VERSION ""

NS_ :

BS_:

BU_: ACU Charger Charging_SDC DGPS DTI_Inverter Dash_Panel Debugger ECU Energy_Meter Fan_Controller_1 Fan_Controller_2 Fan_Controller_3 Fan_Controller_4 Fan_Controller_5 Fan_Controller_6 Fan_Controller_7 Fan_Controller_8 GR_Inverter_1 GR_Inverter_2 GR_Inverter_3 GR_Inverter_4 IMD LV_DC_DC SAM1 SAM10 SAM11 SAM12 SAM13 SAM14 SAM15 SAM16 SAM17 SAM18 SAM19 SAM2 SAM20 SAM3 SAM4 SAM5 SAM6 SAM7 SAM8 SAM9 Steering_Wheel TCM ALL

BO_ 2147680257 ACU_Debug_2_0_to_Debugger: 8 ACU
 SG_ Debug : 0|64@1- (1,0) [0|0] "" Debugger

BO_ 2147680769 ACU_Ping_to_Debugger: 4 ACU
 SG_ Timestamp : 0|32@1+ (1,0) [0|4,294,967,296] "ms" Debugger

BO_ 2147680770 ACU_Ping_to_ECU: 4 ACU
 SG_ Timestamp : 0|32@1+ (1,0) [0|4,294,967,296] "ms" ECU

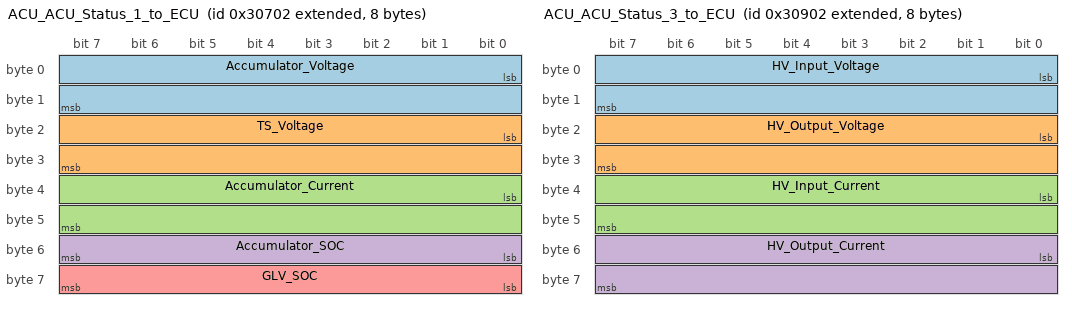
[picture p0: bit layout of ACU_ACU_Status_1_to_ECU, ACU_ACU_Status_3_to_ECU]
BO_ 2147682050 ACU_ACU_Status_1_to_ECU: 8 ACU
 SG_ Accumulator_Voltage : 0|16@1+ (0.01,0) [0|655.35] "Volts" ECU
 SG_ TS_Voltage : 16|16@1+ (0.01,0) [0|655.35] "Volts" ECU
 SG_ Accumulator_Current : 32|16@1- (0.01,0) [-327.68|327.67] "Amps" ECU
 SG_ Accumulator_SOC : 48|8@1+ (0.392157,0) [0|100] "%" ECU
 SG_ GLV_SOC : 56|8@1+ (0.392157,0) [0|100] "%" ECU

BO_ 2147682306 ACU_ACU_Status_2_to_ECU: 7 ACU
 SG_ 20v_Voltage : 0|8@1+ (0.1,0) [0|25.5] "Volts" ECU
 SG_ 12v_Voltage : 8|8@1+ (0.1,0) [0|25.5] "Volts" ECU
 SG_ SDC_Voltage : 16|8@1+ (0.1,0) [0|25.5] "Volts" ECU
 SG_ Min_Cell_Voltage : 24|8@1+ (0.01,2) [2|4.55] "Volts" ECU
 SG_ Max_Cell_Temp : 32|8@1+ (0.25,0) [0|63.75] "Celsius" ECU
 SG_ Over_Temp_Error : 40|1@1+ (1,0) [0|0] "Bool" ECU
 SG_ Over_Voltage_Error : 41|1@1+ (1,0) [0|0] "Bool" ECU
 SG_ Under_Voltage_Error : 42|1@1+ (1,0) [0|0] "Bool" ECU
 SG_ Over_Current_Error : 43|1@1+ (1,0) [0|0] "Bool" ECU
 SG_ Under_Current_Error : 44|1@1+ (1,0) [0|0] "Bool" ECU
 SG_ Under_Voltage_20v_Warning : 45|1@1+ (1,0) [0|0] "Bool" ECU
 SG_ Under_Voltage_12v_Warning : 46|1@1+ (1,0) [0|0] "Bool" ECU
 SG_ Under_Voltage_SDC_Warning : 47|1@1+ (1,0) [0|0] "Bool" ECU
 SG_ Precharge_Error : 48|1@1+ (1,0) [0|0] "Bool" ECU
 SG_ IR__Precharge_State : 49|1@1+ (1,0) [0|0] "Bool" ECU
 SG_ IR_State : 50|1@1+ (1,0) [0|0] "Bool" ECU
 SG_ Software_Latch : 51|1@1+ (1,0) [0|0] "Bool" ECU

BO_ 2147682562 ACU_ACU_Status_3_to_ECU: 8 ACU
 SG_ HV_Input_Voltage : 0|16@1+ (0.01,0) [0|655.35] "Volts" ECU
 SG_ HV_Output_Voltage : 16|16@1+ (0.01,0) [0|655.35] "Volts" ECU
 SG_ HV_Input_Current : 32|16@1+ (0.001,0) [0|65.535] "Amps" ECU
 SG_ HV_Output_Current : 48|16@1+ (0.001,0) [0|65.535] "Amps" ECU

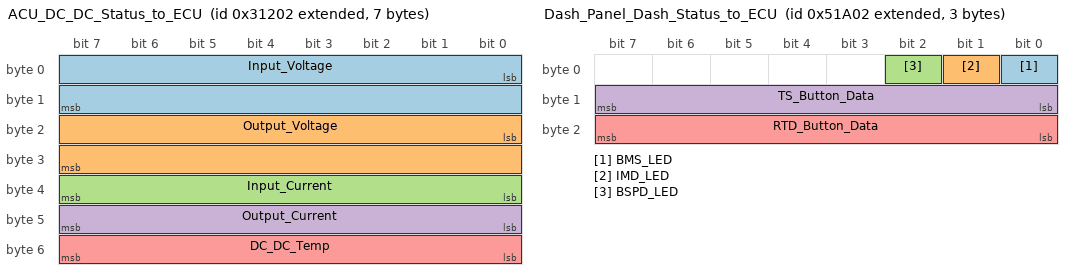
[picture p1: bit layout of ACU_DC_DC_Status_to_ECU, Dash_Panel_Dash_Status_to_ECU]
BO_ 2147684866 ACU_DC_DC_Status_to_ECU: 7 ACU
 SG_ Input_Voltage : 0|16@1+ (0.001,0) [0|65.535] "Volts" ECU
 SG_ Output_Voltage : 16|16@1+ (0.001,0) [0|65.535] "Volts" ECU
 SG_ Input_Current : 32|8@1+ (0.1,0) [0|25.5] "Amps" ECU
 SG_ Output_Current : 40|8@1+ (0.1,0) [0|25.5] "Amps" ECU
 SG_ DC_DC_Temp : 48|8@1+ (1,0) [0|255] "Celsius" ECU

BO_ 2147680513 ACU_Debug_FD_to_Debugger: 64 ACU
 SG_ Debug : 0|64@1- (1,0) [0|0] "" Debugger

BO_ 2147680769 ACU_Ping_to_Debugger: 4 ACU
 SG_ Timestamp : 0|32@1+ (1,0) [0|4,294,967,296] "ms" Debugger

BO_ 2147680770 ACU_Ping_to_ECU: 4 ACU
 SG_ Timestamp : 0|32@1+ (1,0) [0|4,294,967,296] "ms" ECU

BO_ 2147683839 ACU_ACU_Cell_Data_1_to_ALL: 64 ACU
 SG_ Cell_0_Voltage : 0|8@1+ (0.01,2) [2|4.55] "Volts" ALL
 SG_ Cell_0_Temp : 8|8@1+ (0.25,0) [0|63.75] "Celsius" ALL
 SG_ Cell_1_Voltage : 16|8@1+ (0.01,2) [2|4.55] "Volts" ALL
 SG_ Cell_1_Temp : 24|8@1+ (0.25,0) [0|63.75] "Celsius" ALL
 SG_ Cell_2_Voltage : 32|8@1+ (0.01,2) [2|4.55] "Volts" ALL
 SG_ Cell_2_Temp : 40|8@1+ (0.25,0) [0|63.75] "Celsius" ALL
 SG_ Cell_3_Voltage : 48|8@1+ (0.01,2) [2|4.55] "Volts" ALL
 SG_ Cell_3_Temp : 56|8@1+ (0.25,0) [0|63.75] "Celsius" ALL
 SG_ Cell_4_Voltage : 64|8@1+ (0.01,2) [2|4.55] "Volts" ALL
 SG_ Cell_4_Temp : 72|8@1+ (0.25,0) [0|63.75] "Celsius" ALL
 SG_ Cell_5_Voltage : 80|8@1+ (0.01,2) [2|4.55] "Volts" ALL
 SG_ Cell_5_Temp : 88|8@1+ (0.25,0) [0|63.75] "Celsius" ALL
 SG_ Cell_6_Voltage : 96|8@1+ (0.01,2) [2|4.55] "Volts" ALL
 SG_ Cell_6_Temp : 104|8@1+ (0.25,0) [0|63.75] "Celsius" ALL
 SG_ Cell_7_Voltage : 112|8@1+ (0.01,2) [2|4.55] "Volts" ALL
 SG_ Cell_7_Temp : 120|8@1+ (0.25,0) [0|63.75] "Celsius" ALL
 SG_ Cell_8_Voltage : 128|8@1+ (0.01,2) [2|4.55] "Volts" ALL
 SG_ Cell_8_Temp : 136|8@1+ (0.25,0) [0|63.75] "Celsius" ALL
 SG_ Cell_9_Voltage : 144|8@1+ (0.01,2) [2|4.55] "Volts" ALL
 SG_ Cell_9_Temp : 152|8@1+ (0.25,0) [0|63.75] "Celsius" ALL
 SG_ Cell_10_Voltage : 160|8@1+ (0.01,2) [2|4.55] "Volts" ALL
 SG_ Cell_10_Temp : 168|8@1+ (0.25,0) [0|63.75] "Celsius" ALL
 SG_ Cell_11_Voltage : 176|8@1+ (0.01,2) [2|4.55] "Volts" ALL
 SG_ Cell_11_Temp : 184|8@1+ (0.25,0) [0|63.75] "Celsius" ALL
 SG_ Cell_12_Voltage : 192|8@1+ (0.01,2) [2|4.55] "Volts" ALL
 SG_ Cell_12_Temp : 200|8@1+ (0.25,0) [0|63.75] "Celsius" ALL
 SG_ Cell_13_Voltage : 208|8@1+ (0.01,2) [2|4.55] "Volts" ALL
 SG_ Cell_13_Temp : 216|8@1+ (0.25,0) [0|63.75] "Celsius" ALL
 SG_ Cell_14_Voltage : 224|8@1+ (0.01,2) [2|4.55] "Volts" ALL
 SG_ Cell_14_Temp : 232|8@1+ (0.25,0) [0|63.75] "Celsius" ALL
 SG_ Cell_15_Voltage : 240|8@1+ (0.01,2) [2|4.55] "Volts" ALL
 SG_ Cell_15_Temp : 248|8@1+ (0.25,0) [0|63.75] "Celsius" ALL
 SG_ Cell_16_Voltage : 256|8@1+ (0.01,2) [2|4.55] "Volts" ALL
 SG_ Cell_16_Temp : 264|8@1+ (0.25,0) [0|63.75] "Celsius" ALL
 SG_ Cell_17_Voltage : 272|8@1+ (0.01,2) [2|4.55] "Volts" ALL
 SG_ Cell_17_Temp : 280|8@1+ (0.25,0) [0|63.75] "Celsius" ALL
 SG_ Cell_18_Voltage : 288|8@1+ (0.01,2) [2|4.55] "Volts" ALL
 SG_ Cell_18_Temp : 296|8@1+ (0.25,0) [0|63.75] "Celsius" ALL
 SG_ Cell_19_Voltage : 304|8@1+ (0.01,2) [2|4.55] "Volts" ALL
 SG_ Cell_19_Temp : 312|8@1+ (0.25,0) [0|63.75] "Celsius" ALL
 SG_ Cell_20_Voltage : 320|8@1+ (0.01,2) [2|4.55] "Volts" ALL
 SG_ Cell_20_Temp : 328|8@1+ (0.25,0) [0|63.75] "Celsius" ALL
 SG_ Cell_21_Voltage : 336|8@1+ (0.01,2) [2|4.55] "Volts" ALL
 SG_ Cell_21_Temp : 344|8@1+ (0.25,0) [0|63.75] "Celsius" ALL
 SG_ Cell_22_Voltage : 352|8@1+ (0.01,2) [2|4.55] "Volts" ALL
 SG_ Cell_22_Temp : 360|8@1+ (0.25,0) [0|63.75] "Celsius" ALL
 SG_ Cell_23_Voltage : 368|8@1+ (0.01,2) [2|4.55] "Volts" ALL
 SG_ Cell_23_Temp : 376|8@1+ (0.25,0) [0|63.75] "Celsius" ALL
 SG_ Cell_24_Voltage : 384|8@1+ (0.01,2) [2|4.55] "Volts" ALL
 SG_ Cell_24_Temp : 392|8@1+ (0.25,0) [0|63.75] "Celsius" ALL
 SG_ Cell_25_Voltage : 400|8@1+ (0.01,2) [2|4.55] "Volts" ALL
 SG_ Cell_25_Temp : 408|8@1+ (0.25,0) [0|63.75] "Celsius" ALL
 SG_ Cell_26_Voltage : 416|8@1+ (0.01,2) [2|4.55] "Volts" ALL
 SG_ Cell_26_Temp : 424|8@1+ (0.25,0) [0|63.75] "Celsius" ALL
 SG_ Cell_27_Voltage : 432|8@1+ (0.01,2) [2|4.55] "Volts" ALL
 SG_ Cell_27_Temp : 440|8@1+ (0.25,0) [0|63.75] "Celsius" ALL
 SG_ Cell_28_Voltage : 448|8@1+ (0.01,2) [2|4.55] "Volts" ALL
 SG_ Cell_28_Temp : 456|8@1+ (0.25,0) [0|63.75] "Celsius" ALL
 SG_ Cell_29_Voltage : 464|8@1+ (0.01,2) [2|4.55] "Volts" ALL
 SG_ Cell_29_Temp : 472|8@1+ (0.25,0) [0|63.75] "Celsius" ALL
 SG_ Cell_30_Voltage : 480|8@1+ (0.01,2) [2|4.55] "Volts" ALL
 SG_ Cell_30_Temp : 488|8@1+ (0.25,0) [0|63.75] "Celsius" ALL
 SG_ Cell_31_Voltage : 496|8@1+ (0.01,2) [2|4.55] "Volts" ALL
 SG_ Cell_31_Temp : 504|8@1+ (0.25,0) [0|63.75] "Celsius" ALL

BO_ 2147684095 ACU_ACU_Cell_Data_2_to_ALL: 64 ACU
 SG_ Cell_32_Voltage : 0|8@1+ (0.01,2) [2|4.55] "Volts" ALL
 SG_ Cell_32_Temp : 8|8@1+ (0.25,0) [0|63.75] "Celsius" ALL
 SG_ Cell_33_Voltage : 16|8@1+ (0.01,2) [2|4.55] "Volts" ALL
 SG_ Cell_33_Temp : 24|8@1+ (0.25,0) [0|63.75] "Celsius" ALL
 SG_ Cell_34_Voltage : 32|8@1+ (0.01,2) [2|4.55] "Volts" ALL
 SG_ Cell_34_Temp : 40|8@1+ (0.25,0) [0|63.75] "Celsius" ALL
 SG_ Cell_35_Voltage : 48|8@1+ (0.01,2) [2|4.55] "Volts" ALL
 SG_ Cell_35_Temp : 56|8@1+ (0.25,0) [0|63.75] "Celsius" ALL
 SG_ Cell_36_Voltage : 64|8@1+ (0.01,2) [2|4.55] "Volts" ALL
 SG_ Cell_36_Temp : 72|8@1+ (0.25,0) [0|63.75] "Celsius" ALL
 SG_ Cell_37_Voltage : 80|8@1+ (0.01,2) [2|4.55] "Volts" ALL
 SG_ Cell_37_Temp : 88|8@1+ (0.25,0) [0|63.75] "Celsius" ALL
 SG_ Cell_38_Voltage : 96|8@1+ (0.01,2) [2|4.55] "Volts" ALL
 SG_ Cell_38_Temp : 104|8@1+ (0.25,0) [0|63.75] "Celsius" ALL
 SG_ Cell_39_Voltage : 112|8@1+ (0.01,2) [2|4.55] "Volts" ALL
 SG_ Cell_39_Temp : 120|8@1+ (0.25,0) [0|63.75] "Celsius" ALL
 SG_ Cell_40_Voltage : 128|8@1+ (0.01,2) [2|4.55] "Volts" ALL
 SG_ Cell_40_Temp : 136|8@1+ (0.25,0) [0|63.75] "Celsius" ALL
 SG_ Cell_41_Voltage : 144|8@1+ (0.01,2) [2|4.55] "Volts" ALL
 SG_ Cell_41_Temp : 152|8@1+ (0.25,0) [0|63.75] "Celsius" ALL
 SG_ Cell_42_Voltage : 160|8@1+ (0.01,2) [2|4.55] "Volts" ALL
 SG_ Cell_42_Temp : 168|8@1+ (0.25,0) [0|63.75] "Celsius" ALL
 SG_ Cell_43_Voltage : 176|8@1+ (0.01,2) [2|4.55] "Volts" ALL
 SG_ Cell_43_Temp : 184|8@1+ (0.25,0) [0|63.75] "Celsius" ALL
 SG_ Cell_44_Voltage : 192|8@1+ (0.01,2) [2|4.55] "Volts" ALL
 SG_ Cell_44_Temp : 200|8@1+ (0.25,0) [0|63.75] "Celsius" ALL
 SG_ Cell_45_Voltage : 208|8@1+ (0.01,2) [2|4.55] "Volts" ALL
 SG_ Cell_45_Temp : 216|8@1+ (0.25,0) [0|63.75] "Celsius" ALL
 SG_ Cell_46_Voltage : 224|8@1+ (0.01,2) [2|4.55] "Volts" ALL
 SG_ Cell_46_Temp : 232|8@1+ (0.25,0) [0|63.75] "Celsius" ALL
 SG_ Cell_47_Voltage : 240|8@1+ (0.01,2) [2|4.55] "Volts" ALL
 SG_ Cell_47_Temp : 248|8@1+ (0.25,0) [0|63.75] "Celsius" ALL
 SG_ Cell_48_Voltage : 256|8@1+ (0.01,2) [2|4.55] "Volts" ALL
 SG_ Cell_48_Temp : 264|8@1+ (0.25,0) [0|63.75] "Celsius" ALL
 SG_ Cell_49_Voltage : 272|8@1+ (0.01,2) [2|4.55] "Volts" ALL
 SG_ Cell_49_Temp : 280|8@1+ (0.25,0) [0|63.75] "Celsius" ALL
 SG_ Cell_50_Voltage : 288|8@1+ (0.01,2) [2|4.55] "Volts" ALL
 SG_ Cell_50_Temp : 296|8@1+ (0.25,0) [0|63.75] "Celsius" ALL
 SG_ Cell_51_Voltage : 304|8@1+ (0.01,2) [2|4.55] "Volts" ALL
 SG_ Cell_51_Temp : 312|8@1+ (0.25,0) [0|63.75] "Celsius" ALL
 SG_ Cell_52_Voltage : 320|8@1+ (0.01,2) [2|4.55] "Volts" ALL
 SG_ Cell_52_Temp : 328|8@1+ (0.25,0) [0|63.75] "Celsius" ALL
 SG_ Cell_53_Voltage : 336|8@1+ (0.01,2) [2|4.55] "Volts" ALL
 SG_ Cell_53_Temp : 344|8@1+ (0.25,0) [0|63.75] "Celsius" ALL
 SG_ Cell_54_Voltage : 352|8@1+ (0.01,2) [2|4.55] "Volts" ALL
 SG_ Cell_54_Temp : 360|8@1+ (0.25,0) [0|63.75] "Celsius" ALL
 SG_ Cell_55_Voltage : 368|8@1+ (0.01,2) [2|4.55] "Volts" ALL
 SG_ Cell_55_Temp : 376|8@1+ (0.25,0) [0|63.75] "Celsius" ALL
 SG_ Cell_56_Voltage : 384|8@1+ (0.01,2) [2|4.55] "Volts" ALL
 SG_ Cell_56_Temp : 392|8@1+ (0.25,0) [0|63.75] "Celsius" ALL
 SG_ Cell_57_Voltage : 400|8@1+ (0.01,2) [2|4.55] "Volts" ALL
 SG_ Cell_57_Temp : 408|8@1+ (0.25,0) [0|63.75] "Celsius" ALL
 SG_ Cell_58_Voltage : 416|8@1+ (0.01,2) [2|4.55] "Volts" ALL
 SG_ Cell_58_Temp : 424|8@1+ (0.25,0) [0|63.75] "Celsius" ALL
 SG_ Cell_59_Voltage : 432|8@1+ (0.01,2) [2|4.55] "Volts" ALL
 SG_ Cell_59_Temp : 440|8@1+ (0.25,0) [0|63.75] "Celsius" ALL
 SG_ Cell_60_Voltage : 448|8@1+ (0.01,2) [2|4.55] "Volts" ALL
 SG_ Cell_60_Temp : 456|8@1+ (0.25,0) [0|63.75] "Celsius" ALL
 SG_ Cell_61_Voltage : 464|8@1+ (0.01,2) [2|4.55] "Volts" ALL
 SG_ Cell_61_Temp : 472|8@1+ (0.25,0) [0|63.75] "Celsius" ALL
 SG_ Cell_62_Voltage : 480|8@1+ (0.01,2) [2|4.55] "Volts" ALL
 SG_ Cell_62_Temp : 488|8@1+ (0.25,0) [0|63.75] "Celsius" ALL
 SG_ Cell_63_Voltage : 496|8@1+ (0.01,2) [2|4.55] "Volts" ALL
 SG_ Cell_63_Temp : 504|8@1+ (0.25,0) [0|63.75] "Celsius" ALL

BO_ 2147684351 ACU_ACU_Cell_Data_3_to_ALL: 64 ACU
 SG_ Cell_64_Voltage : 0|8@1+ (0.01,2) [2|4.55] "Volts" ALL
 SG_ Cell_64_Temp : 8|8@1+ (0.25,0) [0|63.75] "Celsius" ALL
 SG_ Cell_65_Voltage : 16|8@1+ (0.01,2) [2|4.55] "Volts" ALL
 SG_ Cell_65_Temp : 24|8@1+ (0.25,0) [0|63.75] "Celsius" ALL
 SG_ Cell_66_Voltage : 32|8@1+ (0.01,2) [2|4.55] "Volts" ALL
 SG_ Cell_66_Temp : 40|8@1+ (0.25,0) [0|63.75] "Celsius" ALL
 SG_ Cell_67_Voltage : 48|8@1+ (0.01,2) [2|4.55] "Volts" ALL
 SG_ Cell_67_Temp : 56|8@1+ (0.25,0) [0|63.75] "Celsius" ALL
 SG_ Cell_68_Voltage : 64|8@1+ (0.01,2) [2|4.55] "Volts" ALL
 SG_ Cell_68_Temp : 72|8@1+ (0.25,0) [0|63.75] "Celsius" ALL
 SG_ Cell_69_Voltage : 80|8@1+ (0.01,2) [2|4.55] "Volts" ALL
 SG_ Cell_69_Temp : 88|8@1+ (0.25,0) [0|63.75] "Celsius" ALL
 SG_ Cell_70_Voltage : 96|8@1+ (0.01,2) [2|4.55] "Volts" ALL
 SG_ Cell_70_Temp : 104|8@1+ (0.25,0) [0|63.75] "Celsius" ALL
 SG_ Cell_71_Voltage : 112|8@1+ (0.01,2) [2|4.55] "Volts" ALL
 SG_ Cell_71_Temp : 120|8@1+ (0.25,0) [0|63.75] "Celsius" ALL
 SG_ Cell_72_Voltage : 128|8@1+ (0.01,2) [2|4.55] "Volts" ALL
 SG_ Cell_72_Temp : 136|8@1+ (0.25,0) [0|63.75] "Celsius" ALL
 SG_ Cell_73_Voltage : 144|8@1+ (0.01,2) [2|4.55] "Volts" ALL
 SG_ Cell_73_Temp : 152|8@1+ (0.25,0) [0|63.75] "Celsius" ALL
 SG_ Cell_74_Voltage : 160|8@1+ (0.01,2) [2|4.55] "Volts" ALL
 SG_ Cell_74_Temp : 168|8@1+ (0.25,0) [0|63.75] "Celsius" ALL
 SG_ Cell_75_Voltage : 176|8@1+ (0.01,2) [2|4.55] "Volts" ALL
 SG_ Cell_75_Temp : 184|8@1+ (0.25,0) [0|63.75] "Celsius" ALL
 SG_ Cell_76_Voltage : 192|8@1+ (0.01,2) [2|4.55] "Volts" ALL
 SG_ Cell_76_Temp : 200|8@1+ (0.25,0) [0|63.75] "Celsius" ALL
 SG_ Cell_77_Voltage : 208|8@1+ (0.01,2) [2|4.55] "Volts" ALL
 SG_ Cell_77_Temp : 216|8@1+ (0.25,0) [0|63.75] "Celsius" ALL
 SG_ Cell_78_Voltage : 224|8@1+ (0.01,2) [2|4.55] "Volts" ALL
 SG_ Cell_78_Temp : 232|8@1+ (0.25,0) [0|63.75] "Celsius" ALL
 SG_ Cell_79_Voltage : 240|8@1+ (0.01,2) [2|4.55] "Volts" ALL
 SG_ Cell_79_Temp : 248|8@1+ (0.25,0) [0|63.75] "Celsius" ALL
 SG_ Cell_80_Voltage : 256|8@1+ (0.01,2) [2|4.55] "Volts" ALL
 SG_ Cell_80_Temp : 264|8@1+ (0.25,0) [0|63.75] "Celsius" ALL
 SG_ Cell_81_Voltage : 272|8@1+ (0.01,2) [2|4.55] "Volts" ALL
 SG_ Cell_81_Temp : 280|8@1+ (0.25,0) [0|63.75] "Celsius" ALL
 SG_ Cell_82_Voltage : 288|8@1+ (0.01,2) [2|4.55] "Volts" ALL
 SG_ Cell_82_Temp : 296|8@1+ (0.25,0) [0|63.75] "Celsius" ALL
 SG_ Cell_83_Voltage : 304|8@1+ (0.01,2) [2|4.55] "Volts" ALL
 SG_ Cell_83_Temp : 312|8@1+ (0.25,0) [0|63.75] "Celsius" ALL
 SG_ Cell_84_Voltage : 320|8@1+ (0.01,2) [2|4.55] "Volts" ALL
 SG_ Cell_84_Temp : 328|8@1+ (0.25,0) [0|63.75] "Celsius" ALL
 SG_ Cell_85_Voltage : 336|8@1+ (0.01,2) [2|4.55] "Volts" ALL
 SG_ Cell_85_Temp : 344|8@1+ (0.25,0) [0|63.75] "Celsius" ALL
 SG_ Cell_86_Voltage : 352|8@1+ (0.01,2) [2|4.55] "Volts" ALL
 SG_ Cell_86_Temp : 360|8@1+ (0.25,0) [0|63.75] "Celsius" ALL
 SG_ Cell_87_Voltage : 368|8@1+ (0.01,2) [2|4.55] "Volts" ALL
 SG_ Cell_87_Temp : 376|8@1+ (0.25,0) [0|63.75] "Celsius" ALL
 SG_ Cell_88_Voltage : 384|8@1+ (0.01,2) [2|4.55] "Volts" ALL
 SG_ Cell_88_Temp : 392|8@1+ (0.25,0) [0|63.75] "Celsius" ALL
 SG_ Cell_89_Voltage : 400|8@1+ (0.01,2) [2|4.55] "Volts" ALL
 SG_ Cell_89_Temp : 408|8@1+ (0.25,0) [0|63.75] "Celsius" ALL
 SG_ Cell_90_Voltage : 416|8@1+ (0.01,2) [2|4.55] "Volts" ALL
 SG_ Cell_90_Temp : 424|8@1+ (0.25,0) [0|63.75] "Celsius" ALL
 SG_ Cell_91_Voltage : 432|8@1+ (0.01,2) [2|4.55] "Volts" ALL
 SG_ Cell_91_Temp : 440|8@1+ (0.25,0) [0|63.75] "Celsius" ALL
 SG_ Cell_92_Voltage : 448|8@1+ (0.01,2) [2|4.55] "Volts" ALL
 SG_ Cell_92_Temp : 456|8@1+ (0.25,0) [0|63.75] "Celsius" ALL
 SG_ Cell_93_Voltage : 464|8@1+ (0.01,2) [2|4.55] "Volts" ALL
 SG_ Cell_93_Temp : 472|8@1+ (0.25,0) [0|63.75] "Celsius" ALL
 SG_ Cell_94_Voltage : 480|8@1+ (0.01,2) [2|4.55] "Volts" ALL
 SG_ Cell_94_Temp : 488|8@1+ (0.25,0) [0|63.75] "Celsius" ALL
 SG_ Cell_95_Voltage : 496|8@1+ (0.01,2) [2|4.55] "Volts" ALL
 SG_ Cell_95_Temp : 504|8@1+ (0.25,0) [0|63.75] "Celsius" ALL

BO_ 2147684607 ACU_ACU_Cell_Data_4_to_ALL: 64 ACU
 SG_ Cell_96_Voltage : 0|8@1+ (0.01,2) [2|4.55] "Volts" ALL
 SG_ Cell_96_Temp : 8|8@1+ (0.25,0) [0|63.75] "Celsius" ALL
 SG_ Cell_97_Voltage : 16|8@1+ (0.01,2) [2|4.55] "Volts" ALL
 SG_ Cell_97_Temp : 24|8@1+ (0.25,0) [0|63.75] "Celsius" ALL
 SG_ Cell_98_Voltage : 32|8@1+ (0.01,2) [2|4.55] "Volts" ALL
 SG_ Cell_98_Temp : 40|8@1+ (0.25,0) [0|63.75] "Celsius" ALL
 SG_ Cell_99_Voltage : 48|8@1+ (0.01,2) [2|4.55] "Volts" ALL
 SG_ Cell_99_Temp : 56|8@1+ (0.25,0) [0|63.75] "Celsius" ALL
 SG_ Cell_100_Voltage : 64|8@1+ (0.01,2) [2|4.55] "Volts" ALL
 SG_ Cell_100_Temp : 72|8@1+ (0.25,0) [0|63.75] "Celsius" ALL
 SG_ Cell_101_Voltage : 80|8@1+ (0.01,2) [2|4.55] "Volts" ALL
 SG_ Cell_101_Temp : 88|8@1+ (0.25,0) [0|63.75] "Celsius" ALL
 SG_ Cell_102_Voltage : 96|8@1+ (0.01,2) [2|4.55] "Volts" ALL
 SG_ Cell_102_Temp : 104|8@1+ (0.25,0) [0|63.75] "Celsius" ALL
 SG_ Cell_103_Voltage : 112|8@1+ (0.01,2) [2|4.55] "Volts" ALL
 SG_ Cell_103_Temp : 120|8@1+ (0.25,0) [0|63.75] "Celsius" ALL
 SG_ Cell_104_Voltage : 128|8@1+ (0.01,2) [2|4.55] "Volts" ALL
 SG_ Cell_104_Temp : 136|8@1+ (0.25,0) [0|63.75] "Celsius" ALL
 SG_ Cell_105_Voltage : 144|8@1+ (0.01,2) [2|4.55] "Volts" ALL
 SG_ Cell_105_Temp : 152|8@1+ (0.25,0) [0|63.75] "Celsius" ALL
 SG_ Cell_106_Voltage : 160|8@1+ (0.01,2) [2|4.55] "Volts" ALL
 SG_ Cell_106_Temp : 168|8@1+ (0.25,0) [0|63.75] "Celsius" ALL
 SG_ Cell_107_Voltage : 176|8@1+ (0.01,2) [2|4.55] "Volts" ALL
 SG_ Cell_107_Temp : 184|8@1+ (0.25,0) [0|63.75] "Celsius" ALL
 SG_ Cell_108_Voltage : 192|8@1+ (0.01,2) [2|4.55] "Volts" ALL
 SG_ Cell_108_Temp : 200|8@1+ (0.25,0) [0|63.75] "Celsius" ALL
 SG_ Cell_109_Voltage : 208|8@1+ (0.01,2) [2|4.55] "Volts" ALL
 SG_ Cell_109_Temp : 216|8@1+ (0.25,0) [0|63.75] "Celsius" ALL
 SG_ Cell_110_Voltage : 224|8@1+ (0.01,2) [2|4.55] "Volts" ALL
 SG_ Cell_110_Temp : 232|8@1+ (0.25,0) [0|63.75] "Celsius" ALL
 SG_ Cell_111_Voltage : 240|8@1+ (0.01,2) [2|4.55] "Volts" ALL
 SG_ Cell_111_Temp : 248|8@1+ (0.25,0) [0|63.75] "Celsius" ALL
 SG_ Cell_112_Voltage : 256|8@1+ (0.01,2) [2|4.55] "Volts" ALL
 SG_ Cell_112_Temp : 264|8@1+ (0.25,0) [0|63.75] "Celsius" ALL
 SG_ Cell_113_Voltage : 272|8@1+ (0.01,2) [2|4.55] "Volts" ALL
 SG_ Cell_113_Temp : 280|8@1+ (0.25,0) [0|63.75] "Celsius" ALL
 SG_ Cell_114_Voltage : 288|8@1+ (0.01,2) [2|4.55] "Volts" ALL
 SG_ Cell_114_Temp : 296|8@1+ (0.25,0) [0|63.75] "Celsius" ALL
 SG_ Cell_115_Voltage : 304|8@1+ (0.01,2) [2|4.55] "Volts" ALL
 SG_ Cell_115_Temp : 312|8@1+ (0.25,0) [0|63.75] "Celsius" ALL
 SG_ Cell_116_Voltage : 320|8@1+ (0.01,2) [2|4.55] "Volts" ALL
 SG_ Cell_116_Temp : 328|8@1+ (0.25,0) [0|63.75] "Celsius" ALL
 SG_ Cell_117_Voltage : 336|8@1+ (0.01,2) [2|4.55] "Volts" ALL
 SG_ Cell_117_Temp : 344|8@1+ (0.25,0) [0|63.75] "Celsius" ALL
 SG_ Cell_118_Voltage : 352|8@1+ (0.01,2) [2|4.55] "Volts" ALL
 SG_ Cell_118_Temp : 360|8@1+ (0.25,0) [0|63.75] "Celsius" ALL
 SG_ Cell_119_Voltage : 368|8@1+ (0.01,2) [2|4.55] "Volts" ALL
 SG_ Cell_119_Temp : 376|8@1+ (0.25,0) [0|63.75] "Celsius" ALL
 SG_ Cell_120_Voltage : 384|8@1+ (0.01,2) [2|4.55] "Volts" ALL
 SG_ Cell_120_Temp : 392|8@1+ (0.25,0) [0|63.75] "Celsius" ALL
 SG_ Cell_121_Voltage : 400|8@1+ (0.01,2) [2|4.55] "Volts" ALL
 SG_ Cell_121_Temp : 408|8@1+ (0.25,0) [0|63.75] "Celsius" ALL
 SG_ Cell_122_Voltage : 416|8@1+ (0.01,2) [2|4.55] "Volts" ALL
 SG_ Cell_122_Temp : 424|8@1+ (0.25,0) [0|63.75] "Celsius" ALL
 SG_ Cell_123_Voltage : 432|8@1+ (0.01,2) [2|4.55] "Volts" ALL
 SG_ Cell_123_Temp : 440|8@1+ (0.25,0) [0|63.75] "Celsius" ALL
 SG_ Cell_124_Voltage : 448|8@1+ (0.01,2) [2|4.55] "Volts" ALL
 SG_ Cell_124_Temp : 456|8@1+ (0.25,0) [0|63.75] "Celsius" ALL
 SG_ Cell_125_Voltage : 464|8@1+ (0.01,2) [2|4.55] "Volts" ALL
 SG_ Cell_125_Temp : 472|8@1+ (0.25,0) [0|63.75] "Celsius" ALL
 SG_ Cell_126_Voltage : 480|8@1+ (0.01,2) [2|4.55] "Volts" ALL
 SG_ Cell_126_Temp : 488|8@1+ (0.25,0) [0|63.75] "Celsius" ALL
 SG_ Cell_127_Voltage : 496|8@1+ (0.01,2) [2|4.55] "Volts" ALL
 SG_ Cell_127_Temp : 504|8@1+ (0.25,0) [0|63.75] "Celsius" ALL

BO_ 2147684863 ACU_ACU_Cell_Data_5_to_ALL: 64 ACU
 SG_ Cell_128_Voltage : 0|8@1+ (0.01,2) [2|4.55] "Volts" ALL
 SG_ Cell_128_Temp : 8|8@1+ (0.25,0) [0|63.75] "Celsius" ALL
 SG_ Cell_129_Voltage : 16|8@1+ (0.01,2) [2|4.55] "Volts" ALL
 SG_ Cell_129_Temp : 24|8@1+ (0.25,0) [0|63.75] "Celsius" ALL
 SG_ Cell_130_Voltage : 32|8@1+ (0.01,2) [2|4.55] "Volts" ALL
 SG_ Cell_130_Temp : 40|8@1+ (0.25,0) [0|63.75] "Celsius" ALL
 SG_ Cell_131_Voltage : 48|8@1+ (0.01,2) [2|4.55] "Volts" ALL
 SG_ Cell_131_Temp : 56|8@1+ (0.25,0) [0|63.75] "Celsius" ALL
 SG_ Cell_132_Voltage : 64|8@1+ (0.01,2) [2|4.55] "Volts" ALL
 SG_ Cell_132_Temp : 72|8@1+ (0.25,0) [0|63.75] "Celsius" ALL
 SG_ Cell_133_Voltage : 80|8@1+ (0.01,2) [2|4.55] "Volts" ALL
 SG_ Cell_133_Temp : 88|8@1+ (0.25,0) [0|63.75] "Celsius" ALL
 SG_ Cell_134_Voltage : 96|8@1+ (0.01,2) [2|4.55] "Volts" ALL
 SG_ Cell_134_Temp : 104|8@1+ (0.25,0) [0|63.75] "Celsius" ALL
 SG_ Cell_135_Voltage : 112|8@1+ (0.01,2) [2|4.55] "Volts" ALL
 SG_ Cell_135_Temp : 120|8@1+ (0.25,0) [0|63.75] "Celsius" ALL
 SG_ Cell_136_Voltage : 128|8@1+ (0.01,2) [2|4.55] "Volts" ALL
 SG_ Cell_136_Temp : 136|8@1+ (0.25,0) [0|63.75] "Celsius" ALL
 SG_ Cell_137_Voltage : 144|8@1+ (0.01,2) [2|4.55] "Volts" ALL
 SG_ Cell_137_Temp : 152|8@1+ (0.25,0) [0|63.75] "Celsius" ALL
 SG_ Cell_138_Voltage : 160|8@1+ (0.01,2) [2|4.55] "Volts" ALL
 SG_ Cell_138_Temp : 168|8@1+ (0.25,0) [0|63.75] "Celsius" ALL
 SG_ Cell_139_Voltage : 176|8@1+ (0.01,2) [2|4.55] "Volts" ALL
 SG_ Cell_139_Temp : 184|8@1+ (0.25,0) [0|63.75] "Celsius" ALL
 SG_ Cell_140_Voltage : 192|8@1+ (0.01,2) [2|4.55] "Volts" ALL
 SG_ Cell_140_Temp : 200|8@1+ (0.25,0) [0|63.75] "Celsius" ALL
 SG_ Cell_141_Voltage : 208|8@1+ (0.01,2) [2|4.55] "Volts" ALL
 SG_ Cell_141_Temp : 216|8@1+ (0.25,0) [0|63.75] "Celsius" ALL
 SG_ Cell_142_Voltage : 224|8@1+ (0.01,2) [2|4.55] "Volts" ALL
 SG_ Cell_142_Temp : 232|8@1+ (0.25,0) [0|63.75] "Celsius" ALL
 SG_ Cell_143_Voltage : 240|8@1+ (0.01,2) [2|4.55] "Volts" ALL
 SG_ Cell_143_Temp : 248|8@1+ (0.25,0) [0|63.75] "Celsius" ALL
 SG_ Cell_144_Voltage : 256|8@1+ (0.01,2) [2|4.55] "Volts" ALL
 SG_ Cell_144_Temp : 264|8@1+ (0.25,0) [0|63.75] "Celsius" ALL
 SG_ Cell_145_Voltage : 272|8@1+ (0.01,2) [2|4.55] "Volts" ALL
 SG_ Cell_145_Temp : 280|8@1+ (0.25,0) [0|63.75] "Celsius" ALL
 SG_ Cell_146_Voltage : 288|8@1+ (0.01,2) [2|4.55] "Volts" ALL
 SG_ Cell_146_Temp : 296|8@1+ (0.25,0) [0|63.75] "Celsius" ALL
 SG_ Cell_147_Voltage : 304|8@1+ (0.01,2) [2|4.55] "Volts" ALL
 SG_ Cell_147_Temp : 312|8@1+ (0.25,0) [0|63.75] "Celsius" ALL
 SG_ Cell_148_Voltage : 320|8@1+ (0.01,2) [2|4.55] "Volts" ALL
 SG_ Cell_148_Temp : 328|8@1+ (0.25,0) [0|63.75] "Celsius" ALL
 SG_ Cell_149_Voltage : 336|8@1+ (0.01,2) [2|4.55] "Volts" ALL
 SG_ Cell_149_Temp : 344|8@1+ (0.25,0) [0|63.75] "Celsius" ALL
 SG_ Cell_150_Voltage : 352|8@1+ (0.01,2) [2|4.55] "Volts" ALL
 SG_ Cell_150_Temp : 360|8@1+ (0.25,0) [0|63.75] "Celsius" ALL
 SG_ Cell_151_Voltage : 368|8@1+ (0.01,2) [2|4.55] "Volts" ALL
 SG_ Cell_151_Temp : 376|8@1+ (0.25,0) [0|63.75] "Celsius" ALL
 SG_ Cell_152_Voltage : 384|8@1+ (0.01,2) [2|4.55] "Volts" ALL
 SG_ Cell_152_Temp : 392|8@1+ (0.25,0) [0|63.75] "Celsius" ALL
 SG_ Cell_153_Voltage : 400|8@1+ (0.01,2) [2|4.55] "Volts" ALL
 SG_ Cell_153_Temp : 408|8@1+ (0.25,0) [0|63.75] "Celsius" ALL
 SG_ Cell_154_Voltage : 416|8@1+ (0.01,2) [2|4.55] "Volts" ALL
 SG_ Cell_154_Temp : 424|8@1+ (0.25,0) [0|63.75] "Celsius" ALL
 SG_ Cell_155_Voltage : 432|8@1+ (0.01,2) [2|4.55] "Volts" ALL
 SG_ Cell_155_Temp : 440|8@1+ (0.25,0) [0|63.75] "Celsius" ALL
 SG_ Cell_156_Voltage : 448|8@1+ (0.01,2) [2|4.55] "Volts" ALL
 SG_ Cell_156_Temp : 456|8@1+ (0.25,0) [0|63.75] "Celsius" ALL
 SG_ Cell_157_Voltage : 464|8@1+ (0.01,2) [2|4.55] "Volts" ALL
 SG_ Cell_157_Temp : 472|8@1+ (0.25,0) [0|63.75] "Celsius" ALL
 SG_ Cell_158_Voltage : 480|8@1+ (0.01,2) [2|4.55] "Volts" ALL
 SG_ Cell_158_Temp : 488|8@1+ (0.25,0) [0|63.75] "Celsius" ALL
 SG_ Cell_159_Voltage : 496|8@1+ (0.01,2) [2|4.55] "Volts" ALL
 SG_ Cell_159_Temp : 504|8@1+ (0.25,0) [0|63.75] "Celsius" ALL

BO_ 2550588916 ACU_Charger_Control_to_Charger: 5 ACU

BO_ 2566869221 Charger_Charger_Data_to_ACU: 8 Charger

BO_ 2147811329 Dash_Panel_Debug_2_0_to_Debugger: 8 Dash_Panel
 SG_ Debug : 0|64@1- (1,0) [0|0] "" Debugger

BO_ 2147811841 Dash_Panel_Ping_to_Debugger: 4 Dash_Panel
 SG_ Timestamp : 0|32@1+ (1,0) [0|4,294,967,296] "ms" Debugger

BO_ 2147811842 Dash_Panel_Ping_to_ECU: 4 Dash_Panel
 SG_ Timestamp : 0|32@1+ (1,0) [0|4,294,967,296] "ms" ECU

BO_ 2147817986 Dash_Panel_Dash_Status_to_ECU: 3 Dash_Panel
 SG_ BMS_LED : 0|1@1+ (1,0) [0|0] "Bool" ECU
 SG_ IMD_LED : 1|1@1+ (1,0) [0|0] "Bool" ECU
 SG_ BSPD_LED : 2|1@1+ (1,0) [0|0] "Bool" ECU
 SG_ TS_Button_Data : 8|8@1- (0.1,0) [0|12.7] "Seconds" ECU
 SG_ RTD_Button_Data : 16|8@1- (0.1,0) [0|12.7] "Seconds" ECU

BO_ 2147549186 Debugger_Debug_2_0_to_ECU: 8 Debugger
 SG_ Debug : 0|64@1- (1,0) [0|0] "" ECU

BO_ 2147549698 Debugger_Ping_to_ECU: 4 Debugger
 SG_ Timestamp : 0|32@1+ (1,0) [0|4,294,967,296] "ms" ECU

BO_ 2147550722 Debugger_ECU_config_to_ECU: 0 Debugger

BO_ 2147549187 Debugger_Debug_2_0_to_ACU: 8 Debugger
 SG_ Debug : 0|64@1- (1,0) [0|0] "" ACU

BO_ 2147549699 Debugger_Ping_to_ACU: 4 Debugger
 SG_ Timestamp : 0|32@1+ (1,0) [0|4,294,967,296] "ms" ACU

BO_ 2147549188 Debugger_Debug_2_0_to_TCM: 8 Debugger
 SG_ Debug : 0|64@1- (1,0) [0|0] "" TCM

BO_ 2147549700 Debugger_Ping_to_TCM: 4 Debugger
 SG_ Timestamp : 0|32@1+ (1,0) [0|4,294,967,296] "ms" TCM

BO_ 2147549189 Debugger_Debug_2_0_to_Dash_Panel: 8 Debugger
 SG_ Debug : 0|64@1- (1,0) [0|0] "" Dash_Panel

BO_ 2147549701 Debugger_Ping_to_Dash_Panel: 4 Debugger
 SG_ Timestamp : 0|32@1+ (1,0) [0|4,294,967,296] "ms" Dash_Panel

BO_ 2147549192 Debugger_Debug_2_0_to_GR_Inverter_1: 8 Debugger
 SG_ Debug : 0|64@1- (1,0) [0|0] "" GR_Inverter_1

BO_ 2147549704 Debugger_Ping_to_GR_Inverter_1: 4 Debugger
 SG_ Timestamp : 0|32@1+ (1,0) [0|4,294,967,296] "ms" GR_Inverter_1

BO_ 2147549193 Debugger_Debug_2_0_to_GR_Inverter_2: 8 Debugger
 SG_ Debug : 0|64@1- (1,0) [0|0] "" GR_Inverter_2

BO_ 2147549705 Debugger_Ping_to_GR_Inverter_2: 4 Debugger
 SG_ Timestamp : 0|32@1+ (1,0) [0|4,294,967,296] "ms" GR_Inverter_2

BO_ 2147549194 Debugger_Debug_2_0_to_GR_Inverter_3: 8 Debugger
 SG_ Debug : 0|64@1- (1,0) [0|0] "" GR_Inverter_3

BO_ 2147549706 Debugger_Ping_to_GR_Inverter_3: 4 Debugger
 SG_ Timestamp : 0|32@1+ (1,0) [0|4,294,967,296] "ms" GR_Inverter_3

BO_ 2147549195 Debugger_Debug_2_0_to_GR_Inverter_4: 8 Debugger
 SG_ Debug : 0|64@1- (1,0) [0|0] "" GR_Inverter_4

BO_ 2147549707 Debugger_Ping_to_GR_Inverter_4: 4 Debugger
 SG_ Timestamp : 0|32@1+ (1,0) [0|4,294,967,296] "ms" GR_Inverter_4

BO_ 2147549197 Debugger_Debug_2_0_to_Fan_Controller_1: 8 Debugger
 SG_ Debug : 0|64@1- (1,0) [0|0] "" Fan_Controller_1

BO_ 2147549709 Debugger_Ping_to_Fan_Controller_1: 4 Debugger
 SG_ Timestamp : 0|32@1+ (1,0) [0|4,294,967,296] "ms" Fan_Controller_1

BO_ 2147549198 Debugger_Debug_2_0_to_Fan_Controller_2: 8 Debugger
 SG_ Debug : 0|64@1- (1,0) [0|0] "" Fan_Controller_2

BO_ 2147549710 Debugger_Ping_to_Fan_Controller_2: 4 Debugger
 SG_ Timestamp : 0|32@1+ (1,0) [0|4,294,967,296] "ms" Fan_Controller_2

BO_ 2147549199 Debugger_Debug_2_0_to_Fan_Controller_3: 8 Debugger
 SG_ Debug : 0|64@1- (1,0) [0|0] "" Fan_Controller_3

BO_ 2147549711 Debugger_Ping_to_Fan_Controller_3: 4 Debugger
 SG_ Timestamp : 0|32@1+ (1,0) [0|4,294,967,296] "ms" Fan_Controller_3

BO_ 2147549200 Debugger_Debug_2_0_to_Fan_Controller_4: 8 Debugger
 SG_ Debug : 0|64@1- (1,0) [0|0] "" Fan_Controller_4

BO_ 2147549712 Debugger_Ping_to_Fan_Controller_4: 4 Debugger
 SG_ Timestamp : 0|32@1+ (1,0) [0|4,294,967,296] "ms" Fan_Controller_4

BO_ 2147549201 Debugger_Debug_2_0_to_Fan_Controller_5: 8 Debugger
 SG_ Debug : 0|64@1- (1,0) [0|0] "" Fan_Controller_5

BO_ 2147549713 Debugger_Ping_to_Fan_Controller_5: 4 Debugger
 SG_ Timestamp : 0|32@1+ (1,0) [0|4,294,967,296] "ms" Fan_Controller_5

BO_ 2147549202 Debugger_Debug_2_0_to_Fan_Controller_6: 8 Debugger
 SG_ Debug : 0|64@1- (1,0) [0|0] "" Fan_Controller_6

BO_ 2147549714 Debugger_Ping_to_Fan_Controller_6: 4 Debugger
 SG_ Timestamp : 0|32@1+ (1,0) [0|4,294,967,296] "ms" Fan_Controller_6

BO_ 2147549203 Debugger_Debug_2_0_to_Fan_Controller_7: 8 Debugger
 SG_ Debug : 0|64@1- (1,0) [0|0] "" Fan_Controller_7

BO_ 2147549715 Debugger_Ping_to_Fan_Controller_7: 4 Debugger
 SG_ Timestamp : 0|32@1+ (1,0) [0|4,294,967,296] "ms" Fan_Controller_7

BO_ 2147549204 Debugger_Debug_2_0_to_Fan_Controller_8: 8 Debugger
 SG_ Debug : 0|64@1- (1,0) [0|0] "" Fan_Controller_8

BO_ 2147549716 Debugger_Ping_to_Fan_Controller_8: 4 Debugger
 SG_ Timestamp : 0|32@1+ (1,0) [0|4,294,967,296] "ms" Fan_Controller_8

BO_ 2147549225 Debugger_Debug_2_0_to_LV_DC_DC: 8 Debugger
 SG_ Debug : 0|64@1- (1,0) [0|0] "" LV_DC_DC

BO_ 2147549737 Debugger_Ping_to_LV_DC_DC: 4 Debugger
 SG_ Timestamp : 0|32@1+ (1,0) [0|4,294,967,296] "ms" LV_DC_DC

BO_ 2147549442 Debugger_Debug_FD_to_ECU: 64 Debugger
 SG_ Debug : 0|64@1- (1,0) [0|0] "" ECU

BO_ 2147549698 Debugger_Ping_to_ECU: 4 Debugger
 SG_ Timestamp : 0|32@1+ (1,0) [0|4,294,967,296] "ms" ECU

BO_ 2147549443 Debugger_Debug_FD_to_ACU: 64 Debugger
 SG_ Debug : 0|64@1- (1,0) [0|0] "" ACU

BO_ 2147549699 Debugger_Ping_to_ACU: 4 Debugger
 SG_ Timestamp : 0|32@1+ (1,0) [0|4,294,967,296] "ms" ACU

BO_ 2147549444 Debugger_Debug_FD_to_TCM: 64 Debugger
 SG_ Debug : 0|64@1- (1,0) [0|0] "" TCM

BO_ 2147549700 Debugger_Ping_to_TCM: 4 Debugger
 SG_ Timestamp : 0|32@1+ (1,0) [0|4,294,967,296] "ms" TCM

BO_ 2147549446 Debugger_Debug_FD_to_Steering_Wheel: 64 Debugger
 SG_ Debug : 0|64@1- (1,0) [0|0] "" Steering_Wheel

BO_ 2147549702 Debugger_Ping_to_Steering_Wheel: 4 Debugger
 SG_ Timestamp : 0|32@1+ (1,0) [0|4,294,967,296] "ms" Steering_Wheel

BO_ 2147549708 Debugger_Ping_to_Charging_SDC: 4 Debugger
 SG_ Timestamp : 0|32@1+ (1,0) [0|4,294,967,296] "ms" Charging_SDC

BO_ 2147491862 DTI_Inverter_DTI_Data_1_to_ECU: 8 DTI_Inverter

BO_ 2147492118 DTI_Inverter_DTI_Data_2_to_ECU: 8 DTI_Inverter

BO_ 2147492374 DTI_Inverter_DTI_Data_3_to_ECU: 8 DTI_Inverter

BO_ 2147492630 DTI_Inverter_DTI_Data_4_to_ECU: 8 DTI_Inverter

BO_ 2147492886 DTI_Inverter_DTI_Data_5_to_ECU: 8 DTI_Inverter

BO_ 278 ECU_DTI_Control_1_to_DTI_Inverter: 2 ECU

BO_ 534 ECU_DTI_Control_2_to_DTI_Inverter: 2 ECU

BO_ 790 ECU_DTI_Control_3_to_DTI_Inverter: 4 ECU

BO_ 1046 ECU_DTI_Control_4_to_DTI_Inverter: 2 ECU

BO_ 1302 ECU_DTI_Control_5_to_DTI_Inverter: 2 ECU

BO_ 1558 ECU_DTI_Control_6_to_DTI_Inverter: 2 ECU

BO_ 1814 ECU_DTI_Control_7_to_DTI_Inverter: 1 ECU

BO_ 2147485718 ECU_DTI_Control_8_to_DTI_Inverter: 2 ECU

BO_ 2147485974 ECU_DTI_Control_9_to_DTI_Inverter: 2 ECU

BO_ 2147486230 ECU_DTI_Control_10_to_DTI_Inverter: 2 ECU

BO_ 2147486486 ECU_DTI_Control_11_to_DTI_Inverter: 2 ECU

BO_ 2147486742 ECU_DTI_Control_12_to_DTI_Inverter: 1 ECU

BO_ 2147614721 ECU_Debug_2_0_to_Debugger: 8 ECU
 SG_ Debug : 0|64@1- (1,0) [0|0] "" Debugger

BO_ 2147615233 ECU_Ping_to_Debugger: 4 ECU
 SG_ Timestamp : 0|32@1+ (1,0) [0|4,294,967,296] "ms" Debugger

BO_ 2147615487 ECU_Ping_to_ALL: 4 ECU
 SG_ Timestamp : 0|32@1+ (1,0) [0|4,294,967,296] "ms" ALL

BO_ 2147615743 ECU_ECU_Status_1_to_ALL: 8 ECU
 SG_ ECU_State : 0|8@1+ (1,0) [0|0] "" ALL
 SG_ ACU_Node_Status : 8|1@1+ (1,0) [0|0] "Bool" ALL
 SG_ GR_Inv_1_Status : 9|1@1+ (1,0) [0|0] "Bool" ALL
 SG_ GR_Inv_2_Status : 10|1@1+ (1,0) [0|0] "Bool" ALL
 SG_ GR_Inv_3_Status : 11|1@1+ (1,0) [0|0] "Bool" ALL
 SG_ GR_Inv_4_Status : 12|1@1+ (1,0) [0|0] "Bool" ALL
 SG_ Fan_Controller_1 : 13|1@1+ (1,0) [0|0] "Bool" ALL
 SG_ Fan_Controller_2 : 14|1@1+ (1,0) [0|0] "Bool" ALL
 SG_ Fan_Controller_3 : 15|1@1+ (1,0) [0|0] "Bool" ALL
 SG_ Fan_Controller_4 : 16|1@1+ (1,0) [0|0] "Bool" ALL
 SG_ Fan_Controller_5 : 17|1@1+ (1,0) [0|0] "Bool" ALL
 SG_ Fan_Controller_6 : 18|1@1+ (1,0) [0|0] "Bool" ALL
 SG_ Fan_Controller_7 : 19|1@1+ (1,0) [0|0] "Bool" ALL
 SG_ Fan_Controller_8 : 20|1@1+ (1,0) [0|0] "Bool" ALL
 SG_ Dash : 21|1@1+ (1,0) [0|0] "Bool" ALL
 SG_ Steering : 22|1@1+ (1,0) [0|0] "Bool" ALL
 SG_ Power_Level : 32|4@1+ (1,0) [0|0] "" ALL
 SG_ Torque_Map : 36|4@1+ (1,0) [0|0] "" ALL
 SG_ Max_Cell_Temp : 40|8@1+ (0.25,0) [0|63.75] "Celsius" ALL
 SG_ Accumulator_State_of_Charge : 48|8@1+ (0.392157,0) [0|100] "%" ALL
 SG_ GLV_State_of_Charge : 56|8@1+ (0.392157,0) [0|100] "%" ALL

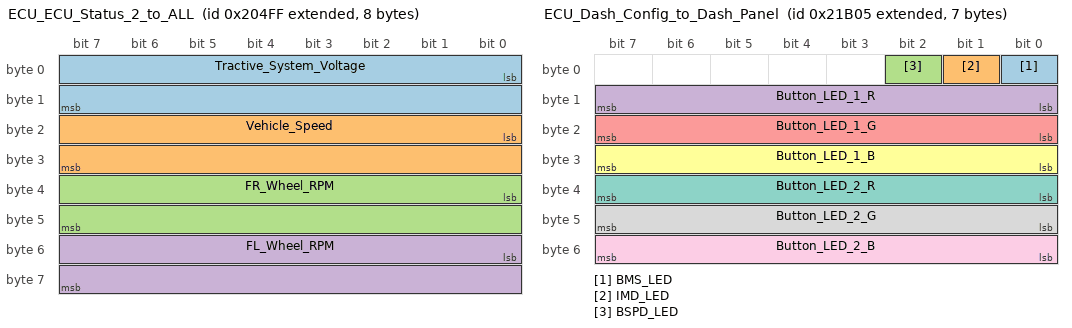
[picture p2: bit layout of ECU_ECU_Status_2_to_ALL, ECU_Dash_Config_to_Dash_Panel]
BO_ 2147615999 ECU_ECU_Status_2_to_ALL: 8 ECU
 SG_ Tractive_System_Voltage : 0|16@1+ (0.01,0) [0|655.35] "Volts" ALL
 SG_ Vehicle_Speed : 16|16@1+ (0.01,0) [0|655.35] "MPH" ALL
 SG_ FR_Wheel_RPM : 32|16@1+ (0.1,-3276.8) [-3276.8|3276.7] "RPM" ALL
 SG_ FL_Wheel_RPM : 48|16@1+ (0.1,-3276.8) [-3276.8|3276.7] "RPM" ALL

BO_ 2147616255 ECU_ECU_Status_3_to_ALL: 4 ECU
 SG_ RR_Wheel_RPM : 0|16@1+ (0.1,-3276.8) [-3276.8|3276.7] "RPM" ALL
 SG_ RL_Wheel_RPM : 16|16@1+ (0.1,-3276.8) [-3276.8|3276.7] "RPM" ALL

BO_ 2147617283 ECU_ACU_Precharge_to_ACU: 1 ECU
 SG_ Set_TS_Active : 0|1@1+ (1,0) [0|0] "Bool" ACU

BO_ 2147617539 ECU_ACU_Config_Charge_Parameters_to_ACU: 4 ECU
 SG_ Charge_Voltage : 0|16@1+ (0.1,0) [0|6553.5] "Volts" ACU
 SG_ Charge_Current : 16|16@1+ (0.1,0) [0|6553.5] "Amps" ACU

BO_ 2147617795 ECU_ACU_Config_Operational_Parameters_to_ACU: 2 ECU
 SG_ Minimium_Cell_Voltage : 0|8@1+ (0.01,2) [2|4.55] "Volts" ACU
 SG_ Max_Cell_Temperature : 8|8@1+ (0.25,0) [0|63.75] "Celsius" ACU

BO_ 2147621637 ECU_Dash_Config_to_Dash_Panel: 7 ECU
 SG_ BMS_LED : 0|1@1+ (1,0) [0|0] "Bool" Dash_Panel
 SG_ IMD_LED : 1|1@1+ (1,0) [0|0] "Bool" Dash_Panel
 SG_ BSPD_LED : 2|1@1+ (1,0) [0|0] "Bool" Dash_Panel
 SG_ Button_LED_1_R : 8|8@1+ (1,0) [0|255] "RGB" Dash_Panel
 SG_ Button_LED_1_G : 16|8@1+ (1,0) [0|255] "RGB" Dash_Panel
 SG_ Button_LED_1_B : 24|8@1+ (1,0) [0|255] "RGB" Dash_Panel
 SG_ Button_LED_2_R : 32|8@1+ (1,0) [0|255] "RGB" Dash_Panel
 SG_ Button_LED_2_G : 40|8@1+ (1,0) [0|255] "RGB" Dash_Panel
 SG_ Button_LED_2_B : 48|8@1+ (1,0) [0|255] "RGB" Dash_Panel

BO_ 2147625733 ECU_Dash_Warning_Flags_to_Dash_Panel: 1 ECU
 SG_ BSE_APPS_Violation : 0|1@1+ (1,0) [0|0] "Bool" Dash_Panel

BO_ 2147625989 ECU_Specific_Brake_IR_to_Dash_Panel: 2 ECU
 SG_ Wheel_identifier : 0|8@1+ (1,0) [0|0] "" Dash_Panel
 SG_ Temp : 8|8@1+ (1,0) [0|255] "Celsius" Dash_Panel

BO_ 2147614977 ECU_Debug_FD_to_Debugger: 64 ECU
 SG_ Debug : 0|64@1- (1,0) [0|0] "" Debugger

BO_ 2147615233 ECU_Ping_to_Debugger: 4 ECU
 SG_ Timestamp : 0|32@1+ (1,0) [0|4,294,967,296] "ms" Debugger

BO_ 2147615487 ECU_Ping_to_ALL: 4 ECU
 SG_ Timestamp : 0|32@1+ (1,0) [0|4,294,967,296] "ms" ALL

BO_ 2147622150 ECU_Steering_Config_to_Steering_Wheel: 0 ECU

BO_ 2147626246 ECU_ECU_Ping_Information_to_Steering_Wheel: 3 ECU
 SG_ Online_pings : 0|24@1+ (1,0) [0|0] "Bool map" Steering_Wheel

BO_ 2147626500 ECU_ECU_Pedals_Data_to_TCM: 10 ECU
 SG_ APPS1_SIGNAL : 0|16@1+ (0.0015259,0) [0|100] "%" TCM
 SG_ APPS2_SIGNAL : 16|16@1+ (0.0015259,0) [0|100] "%" TCM
 SG_ BSE_SIGNAL : 32|16@1+ (0.0015259,0) [0|100] "%" TCM
 SG_ BRAKE_R_SIGNAL : 48|16@1+ (0.0015259,0) [0|100] "%" TCM
 SG_ BRAKE_F_SIGNAL : 48|16@1+ (0.0015259,0) [0|100] "%" TCM

BO_ 269 Energy_Meter_EM_Measurement_to_ACU: 8 Energy_Meter

BO_ 781 Energy_Meter_EM_Team_Data_1_to_ACU: 8 Energy_Meter

BO_ 782 Energy_Meter_EM_Team_Data_2_to_ACU: 8 Energy_Meter

BO_ 1037 Energy_Meter_EM_Status_to_ACU: 8 Energy_Meter

BO_ 1549 Energy_Meter_EM_Temperature_to_ACU: 8 Energy_Meter

BO_ 35 IMD_IMD_response_to_ACU: 0 IMD

BO_ 2565862654 IMD_IMD_isolation_info_to_ACU: 0 IMD

BO_ 2565862654 IMD_IMD_voltage_to_ACU: 0 IMD

BO_ 2565862654 IMD_IMD_IT_system_to_ACU: 0 IMD

BO_ 2565862654 IMD_IMD_request_to_ACU: 0 IMD

BO_ 2566849012 IMD_IMD_general_to_ACU: 8 IMD

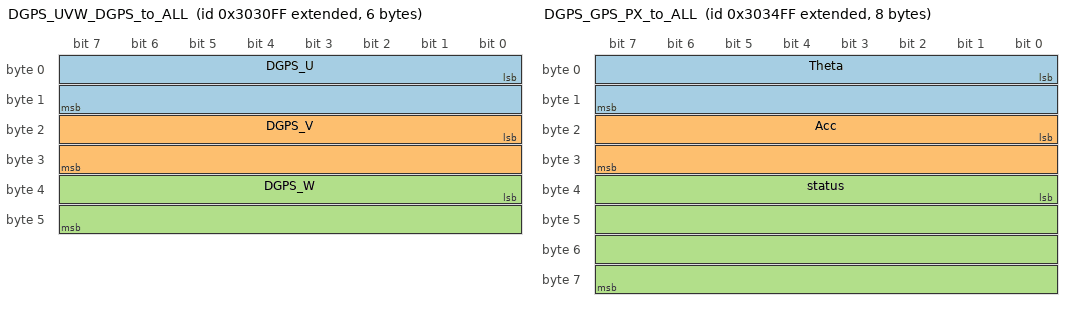
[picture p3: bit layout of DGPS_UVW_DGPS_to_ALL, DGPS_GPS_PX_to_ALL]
BO_ 2150641919 DGPS_UVW_DGPS_to_ALL: 6 DGPS
 SG_ DGPS_U : 0|16@1- (0.01,0) [0|0] "" ALL
 SG_ DGPS_V : 16|16@1- (0.01,0) [0|0] "" ALL
 SG_ DGPS_W : 32|16@1- (0.01,0) [0|0] "" ALL

BO_ 2150642175 DGPS_GPS_LAT_to_ALL: 8 DGPS
 SG_ LAT : 0|64@1+ (1,0) [0|0] "" ALL

BO_ 2150642431 DGPS_GPS_LON_to_ALL: 8 DGPS
 SG_ LON : 0|64@1+ (1,0) [0|0] "" ALL

BO_ 2150642687 DGPS_GPS_ALT_to_ALL: 8 DGPS
 SG_ ALT : 0|64@1+ (1,0) [0|0] "" ALL

BO_ 2150642943 DGPS_GPS_PX_to_ALL: 8 DGPS
 SG_ Theta : 0|16@1- (0.001,0) [0|0] "" ALL
 SG_ Acc : 16|16@1- (0.01,0) [0|0] "" ALL
 SG_ status : 32|32@1+ (1,0) [0|0] "" ALL

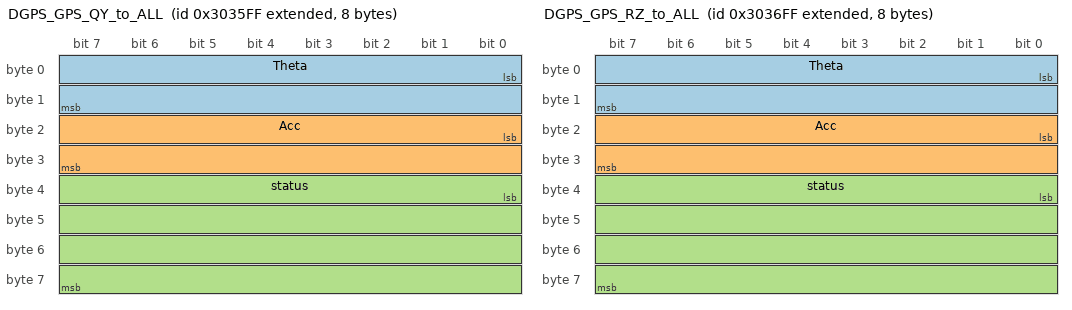
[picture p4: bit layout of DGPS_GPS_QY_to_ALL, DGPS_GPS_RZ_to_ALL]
BO_ 2150643199 DGPS_GPS_QY_to_ALL: 8 DGPS
 SG_ Theta : 0|16@1- (0.001,0) [0|0] "" ALL
 SG_ Acc : 16|16@1- (0.01,0) [0|0] "" ALL
 SG_ status : 32|32@1+ (1,0) [0|0] "" ALL

BO_ 2150643455 DGPS_GPS_RZ_to_ALL: 8 DGPS
 SG_ Theta : 0|16@1- (0.001,0) [0|0] "" ALL
 SG_ Acc : 16|16@1- (0.01,0) [0|0] "" ALL
 SG_ status : 32|32@1+ (1,0) [0|0] "" ALL
